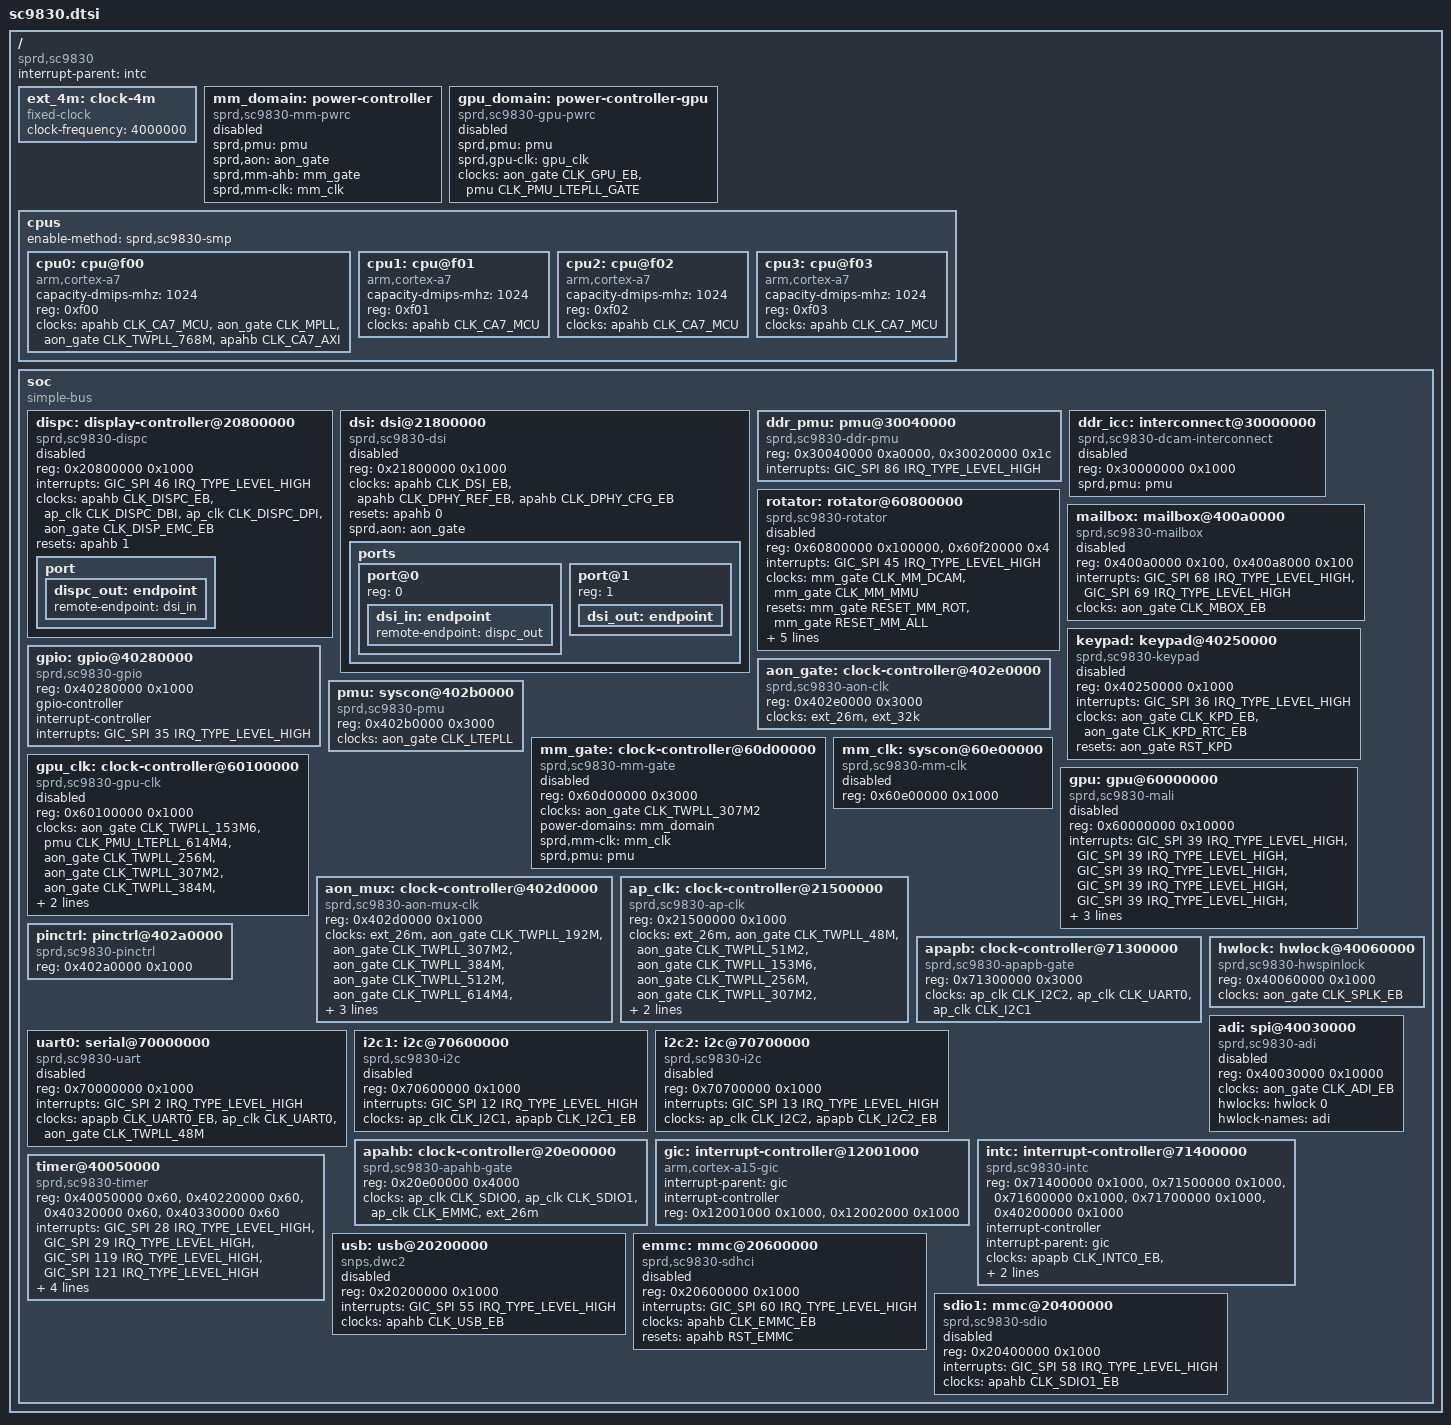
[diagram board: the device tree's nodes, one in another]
// SPDX-License-Identifier: GPL-2.0-only
#include <dt-bindings/interrupt-controller/arm-gic.h>
#include <dt-bindings/clock/sprd,sc9830-clk.h>
#include <dt-bindings/clock/sprd,sc9830-mm-clk.h>
#include <dt-bindings/interconnect/sprd,sc9830.h>
#include <dt-bindings/reset/sprd,sc9830-reset.h>
#include <dt-bindings/reset/sprd,sc9830-mm-reset.h>
#include <dt-bindings/gpio/gpio.h>

/ {
	compatible = "sprd,sc9830";
	#address-cells = <1>;
	#size-cells = <1>;
	interrupt-parent = <&intc>;

	ext_4m: clock-4m {
		compatible = "fixed-clock";
		#clock-cells = <0>;
		clock-frequency = <4000000>;
	};

	mm_domain: power-controller {
		compatible = "sprd,sc9830-mm-pwrc";
		#power-domain-cells = <0>;
		sprd,pmu = <&pmu>;
		sprd,aon = <&aon_gate>;
		sprd,mm-ahb = <&mm_gate>;
		sprd,mm-clk = <&mm_clk>;
		status = "disabled";
	};

	gpu_domain: power-controller-gpu {
		compatible = "sprd,sc9830-gpu-pwrc";
		#power-domain-cells = <0>;
		sprd,pmu = <&pmu>;
		sprd,gpu-clk = <&gpu_clk>;
		clocks = <&aon_gate CLK_GPU_EB>, <&pmu CLK_PMU_LTEPLL_GATE>;
		clock-names = "bus", "source";
		status = "disabled";
	};

	cpus {
		#address-cells = <1>;
		#size-cells = <0>;
		enable-method = "sprd,sc9830-smp";

		cpu0: cpu@f00 {
			device_type = "cpu";
			compatible = "arm,cortex-a7";
			capacity-dmips-mhz = <1024>;
			reg = <0xf00>;
			clocks = <&apahb CLK_CA7_MCU>, <&aon_gate CLK_MPLL>,
				 <&aon_gate CLK_TWPLL_768M>, <&apahb CLK_CA7_AXI>;
			clock-names = "cpu", "mpll", "intermediate", "axi";
		};

		cpu1: cpu@f01 {
			device_type = "cpu";
			compatible = "arm,cortex-a7";
			capacity-dmips-mhz = <1024>;
			reg = <0xf01>;
			clocks = <&apahb CLK_CA7_MCU>;
			clock-names = "cpu";
		};

		cpu2: cpu@f02 {
			device_type = "cpu";
			compatible = "arm,cortex-a7";
			capacity-dmips-mhz = <1024>;
			reg = <0xf02>;
			clocks = <&apahb CLK_CA7_MCU>;
			clock-names = "cpu";
		};

		cpu3: cpu@f03 {
			device_type = "cpu";
			compatible = "arm,cortex-a7";
			capacity-dmips-mhz = <1024>;
			reg = <0xf03>;
			clocks = <&apahb CLK_CA7_MCU>;
			clock-names = "cpu";
		};
	};

	soc {
		compatible = "simple-bus";
		#address-cells = <1>;
		#size-cells = <1>;
		ranges;

		dispc: display-controller@20800000 {
			compatible = "sprd,sc9830-dispc";
			reg = <0x20800000 0x1000>;
			interrupts = <GIC_SPI 46 IRQ_TYPE_LEVEL_HIGH>;
			clocks = <&apahb CLK_DISPC_EB>, <&ap_clk CLK_DISPC_DBI>,
				 <&ap_clk CLK_DISPC_DPI>, <&aon_gate CLK_DISP_EMC_EB>;
			clock-names = "core", "dbi", "dpi", "emc";
			resets = <&apahb 1>;
			status = "disabled";

			port {
				dispc_out: endpoint {
					remote-endpoint = <&dsi_in>;
				};
			};
		};

		dsi: dsi@21800000 {
			compatible = "sprd,sc9830-dsi";
			reg = <0x21800000 0x1000>;
			clocks = <&apahb CLK_DSI_EB>, <&apahb CLK_DPHY_REF_EB>,
				 <&apahb CLK_DPHY_CFG_EB>;
			clock-names = "pclk", "ref", "cfg";
			resets = <&apahb 0>;
			reset-names = "apb";
			sprd,aon = <&aon_gate>;
			status = "disabled";

			ports {
				#address-cells = <1>;
				#size-cells = <0>;

				port@0 {
					reg = <0>;

					dsi_in: endpoint {
						remote-endpoint = <&dispc_out>;
					};
				};

				port@1 {
					reg = <1>;

					dsi_out: endpoint {
					};
				};
			};
		};

		ddr_pmu: pmu@30040000 {
			compatible = "sprd,sc9830-ddr-pmu";
			reg = <0x30040000 0xa0000>, <0x30020000 0x1c>;
			reg-names = "axi", "pub";
			interrupts = <GIC_SPI 86 IRQ_TYPE_LEVEL_HIGH>;
		};

		ddr_icc: interconnect@30000000 {
			compatible = "sprd,sc9830-dcam-interconnect";
			reg = <0x30000000 0x1000>;
			#interconnect-cells = <1>;
			sprd,pmu = <&pmu>;
			status = "disabled";
		};

		rotator: rotator@60800000 {
			compatible = "sprd,sc9830-rotator";
			reg = <0x60800000 0x100000>, <0x60f20000 0x4>;
			reg-names = "dcam", "mmu";
			interrupts = <GIC_SPI 45 IRQ_TYPE_LEVEL_HIGH>;
			clocks = <&mm_gate CLK_MM_DCAM>, <&mm_gate CLK_MM_MMU>;
			clock-names = "dcam", "mmu";
			resets = <&mm_gate RESET_MM_ROT>, <&mm_gate RESET_MM_ALL>;
			reset-names = "rotator", "all";
			power-domains = <&mm_domain>;
			interconnects = <&ddr_icc MASTER_DCAM &ddr_icc SLAVE_DDR>;
			interconnect-names = "dcam-ddr";
			sprd,pmu = <&pmu>;
			sprd,mm-ahb = <&mm_gate>;
			status = "disabled";
		};

		mailbox: mailbox@400a0000 {
			compatible = "sprd,sc9830-mailbox";
			reg = <0x400a0000 0x100>, <0x400a8000 0x100>;
			#mbox-cells = <1>;
			interrupts = <GIC_SPI 68 IRQ_TYPE_LEVEL_HIGH>,
				     <GIC_SPI 69 IRQ_TYPE_LEVEL_HIGH>;
			interrupt-names = "inbox", "outbox";
			clocks = <&aon_gate CLK_MBOX_EB>;
			clock-names = "enable";
			status = "disabled";
		};

		keypad: keypad@40250000 {
			compatible = "sprd,sc9830-keypad";
			reg = <0x40250000 0x1000>;
			interrupts = <GIC_SPI 36 IRQ_TYPE_LEVEL_HIGH>;
			clocks = <&aon_gate CLK_KPD_EB>, <&aon_gate CLK_KPD_RTC_EB>;
			clock-names = "apb", "rtc";
			resets = <&aon_gate RST_KPD>;
			status = "disabled";
		};

		gpio: gpio@40280000 {
			compatible = "sprd,sc9830-gpio", "sprd,sc9860-gpio";
			reg = <0x40280000 0x1000>;
			gpio-controller;
			#gpio-cells = <2>;
			interrupt-controller;
			#interrupt-cells = <2>;
			interrupts = <GIC_SPI 35 IRQ_TYPE_LEVEL_HIGH>;
		};

		aon_gate: clock-controller@402e0000 {
			compatible = "sprd,sc9830-aon-clk", "syscon";
			reg = <0x402e0000 0x3000>;
			#clock-cells = <1>;
			#reset-cells = <1>;
			clocks = <&ext_26m>, <&ext_32k>;
			clock-names = "ext-26m", "ext-32k";
		};

		pmu: syscon@402b0000 {
			compatible = "sprd,sc9830-pmu", "syscon";
			reg = <0x402b0000 0x3000>;
			#clock-cells = <1>;
			clocks = <&aon_gate CLK_LTEPLL>;
			clock-names = "ltepll";
		};

		mm_gate: clock-controller@60d00000 {
			compatible = "sprd,sc9830-mm-gate", "syscon";
			reg = <0x60d00000 0x3000>;
			#clock-cells = <1>;
			#reset-cells = <1>;
			clocks = <&aon_gate CLK_TWPLL_307M2>;
			clock-names = "dcam-source";
			power-domains = <&mm_domain>;
			sprd,mm-clk = <&mm_clk>;
			sprd,pmu = <&pmu>;
			status = "disabled";
		};

		mm_clk: syscon@60e00000 {
			compatible = "sprd,sc9830-mm-clk", "syscon";
			reg = <0x60e00000 0x1000>;
			status = "disabled";
		};

		gpu_clk: clock-controller@60100000 {
			compatible = "sprd,sc9830-gpu-clk", "syscon";
			reg = <0x60100000 0x1000>;
			#clock-cells = <0>;
			clocks = <&aon_gate CLK_TWPLL_153M6>,
				 <&pmu CLK_PMU_LTEPLL_614M4>,
				 <&aon_gate CLK_TWPLL_256M>,
				 <&aon_gate CLK_TWPLL_307M2>,
				 <&aon_gate CLK_TWPLL_384M>,
				 <&aon_gate CLK_TWPLL_512M>;
			power-domains = <&gpu_domain>;
			status = "disabled";
		};

		gpu: gpu@60000000 {
			compatible = "sprd,sc9830-mali", "arm,mali-400";
			reg = <0x60000000 0x10000>;
			interrupts = <GIC_SPI 39 IRQ_TYPE_LEVEL_HIGH>,
				     <GIC_SPI 39 IRQ_TYPE_LEVEL_HIGH>,
				     <GIC_SPI 39 IRQ_TYPE_LEVEL_HIGH>,
				     <GIC_SPI 39 IRQ_TYPE_LEVEL_HIGH>,
				     <GIC_SPI 39 IRQ_TYPE_LEVEL_HIGH>,
				     <GIC_SPI 39 IRQ_TYPE_LEVEL_HIGH>;
			interrupt-names = "gp", "gpmmu", "pp0", "ppmmu0",
					  "pp1", "ppmmu1";
			clocks = <&aon_gate CLK_GPU_EB>, <&gpu_clk>;
			clock-names = "bus", "core";
			power-domains = <&gpu_domain>;
			status = "disabled";
		};

		aon_mux: clock-controller@402d0000 {
			compatible = "sprd,sc9830-aon-mux-clk";
			reg = <0x402d0000 0x1000>;
			#clock-cells = <1>;
			clocks = <&ext_26m>, <&aon_gate CLK_TWPLL_192M>,
				 <&aon_gate CLK_TWPLL_307M2>, <&aon_gate CLK_TWPLL_384M>,
				 <&aon_gate CLK_TWPLL_512M>, <&aon_gate CLK_TWPLL_614M4>,
				 <&aon_gate CLK_TWPLL_768M>, <&aon_gate CLK_DPLL>,
				 <&ext_4m>, <&aon_gate CLK_TWPLL_76M8>,
				 <&aon_gate CLK_TWPLL_96M>;
			clock-names = "ext-26m", "twpll-192m", "twpll-307m2",
				      "twpll-384m", "twpll-512m", "twpll-614m4",
				      "twpll-768m", "dpll", "ext-4m",
				      "twpll-76m8", "twpll-96m";
		};

		ap_clk: clock-controller@21500000 {
			compatible = "sprd,sc9830-ap-clk";
			reg = <0x21500000 0x1000>;
			#clock-cells = <1>;
			clocks = <&ext_26m>, <&aon_gate CLK_TWPLL_48M>,
				 <&aon_gate CLK_TWPLL_51M2>, <&aon_gate CLK_TWPLL_153M6>,
				 <&aon_gate CLK_TWPLL_256M>, <&aon_gate CLK_TWPLL_307M2>,
				 <&aon_gate CLK_TWPLL_384M>, <&aon_gate CLK_TWPLL_96M>;
			clock-names = "ext-26m", "twpll-48m", "twpll-51m2",
				      "twpll-153m6", "twpll-256m", "twpll-307m2",
				      "twpll-384m", "twpll-96m";
			status = "okay";
		};

		apapb: clock-controller@71300000 {
			compatible = "sprd,sc9830-apapb-gate";
			reg = <0x71300000 0x3000>;
			#clock-cells = <1>;
			clocks = <&ap_clk CLK_I2C2>, <&ap_clk CLK_UART0>,
				 <&ap_clk CLK_I2C1>;
			clock-names = "i2c2", "uart0", "i2c1";
			status = "okay";
		};

		pinctrl: pinctrl@402a0000 {
			compatible = "sprd,sc9830-pinctrl";
			reg = <0x402a0000 0x1000>;
			status = "okay";
		};

		uart0: serial@70000000 {
			compatible = "sprd,sc9830-uart", "sprd,sc9836-uart";
			reg = <0x70000000 0x1000>;
			interrupts = <GIC_SPI 2 IRQ_TYPE_LEVEL_HIGH>;
			clocks = <&apapb CLK_UART0_EB>, <&ap_clk CLK_UART0>,
				 <&aon_gate CLK_TWPLL_48M>;
			clock-names = "enable", "uart", "source";
			status = "disabled";
		};

		i2c1: i2c@70600000 {
			compatible = "sprd,sc9830-i2c";
			reg = <0x70600000 0x1000>;
			interrupts = <GIC_SPI 12 IRQ_TYPE_LEVEL_HIGH>;
			clocks = <&ap_clk CLK_I2C1>, <&apapb CLK_I2C1_EB>;
			clock-names = "i2c", "enable";
			#address-cells = <1>;
			#size-cells = <0>;
			status = "disabled";
		};

		i2c2: i2c@70700000 {
			compatible = "sprd,sc9830-i2c";
			reg = <0x70700000 0x1000>;
			interrupts = <GIC_SPI 13 IRQ_TYPE_LEVEL_HIGH>;
			clocks = <&ap_clk CLK_I2C2>, <&apapb CLK_I2C2_EB>;
			clock-names = "i2c", "enable";
			#address-cells = <1>;
			#size-cells = <0>;
			status = "disabled";
		};

		hwlock: hwlock@40060000 {
			compatible = "sprd,sc9830-hwspinlock";
			reg = <0x40060000 0x1000>;
			clocks = <&aon_gate CLK_SPLK_EB>;
			clock-names = "enable";
			#hwlock-cells = <1>;
		};

		adi: spi@40030000 {
			compatible = "sprd,sc9830-adi";
			reg = <0x40030000 0x10000>;
			clocks = <&aon_gate CLK_ADI_EB>;
			hwlocks = <&hwlock 0>;
			hwlock-names = "adi";
			#address-cells = <1>;
			#size-cells = <0>;
			status = "disabled";
		};

		apahb: clock-controller@20e00000 {
			compatible = "sprd,sc9830-apahb-gate";
			reg = <0x20e00000 0x4000>;
			#clock-cells = <1>;
			clocks = <&ap_clk CLK_SDIO0>, <&ap_clk CLK_SDIO1>,
				 <&ap_clk CLK_EMMC>, <&ext_26m>;
			clock-names = "sdio0", "sdio1", "emmc", "ext-26m";
			#reset-cells = <1>;
		};

		gic: interrupt-controller@12001000 {
			interrupt-parent = <&gic>;
			compatible = "arm,cortex-a15-gic";
			#interrupt-cells = <3>;
			#address-cells = <0>;
			interrupt-controller;
			reg = <0x12001000 0x1000>, <0x12002000 0x1000>;
		};

		intc: interrupt-controller@71400000 {
			compatible = "sprd,sc9830-intc";
			reg = <0x71400000 0x1000>, <0x71500000 0x1000>,
			      <0x71600000 0x1000>, <0x71700000 0x1000>,
			      <0x40200000 0x1000>;
			reg-names = "intc0", "intc1", "intc2", "intc3", "aon";
			interrupt-controller;
			#interrupt-cells = <3>;
			#address-cells = <0>;
			interrupt-parent = <&gic>;
			clocks = <&apapb CLK_INTC0_EB>, <&apapb CLK_INTC1_EB>,
				 <&apapb CLK_INTC2_EB>, <&apapb CLK_INTC3_EB>,
				 <&aon_gate CLK_AON_INTC_EB>;
			clock-names = "intc0", "intc1", "intc2", "intc3", "aon";
		};

		timer@40050000 {
			compatible = "sprd,sc9830-timer";
			reg = <0x40050000 0x60>, <0x40220000 0x60>,
			      <0x40320000 0x60>, <0x40330000 0x60>;
			interrupts = <GIC_SPI 28 IRQ_TYPE_LEVEL_HIGH>,
				     <GIC_SPI 29 IRQ_TYPE_LEVEL_HIGH>,
				     <GIC_SPI 119 IRQ_TYPE_LEVEL_HIGH>,
				     <GIC_SPI 121 IRQ_TYPE_LEVEL_HIGH>;
			clocks = <&aon_gate CLK_AON_TMR_EB>,
				 <&aon_gate CLK_AP_TMR0_EB>,
				 <&aon_gate CLK_AP_TMR1_EB>,
				 <&aon_gate CLK_AP_TMR2_EB>;
		};

		usb: usb@20200000 {
			compatible = "snps,dwc2";
			reg = <0x20200000 0x1000>;
			interrupts = <GIC_SPI 55 IRQ_TYPE_LEVEL_HIGH>;
			clocks = <&apahb CLK_USB_EB>;
			clock-names = "otg";
			status = "disabled";
		};

		emmc: mmc@20600000 {
			compatible = "sprd,sc9830-sdhci";
			reg = <0x20600000 0x1000>;
			interrupts = <GIC_SPI 60 IRQ_TYPE_LEVEL_HIGH>;
			clocks = <&apahb CLK_EMMC_EB>;
			resets = <&apahb RST_EMMC>;
			reset-names = "host";
			status = "disabled";
		};

		sdio1: mmc@20400000 {
			#address-cells = <1>;
			#size-cells = <0>;
			compatible = "sprd,sc9830-sdio";
			reg = <0x20400000 0x1000>;
			interrupts = <GIC_SPI 58 IRQ_TYPE_LEVEL_HIGH>;
			clocks = <&apahb CLK_SDIO1_EB>;
			status = "disabled";
		};
	};
};
